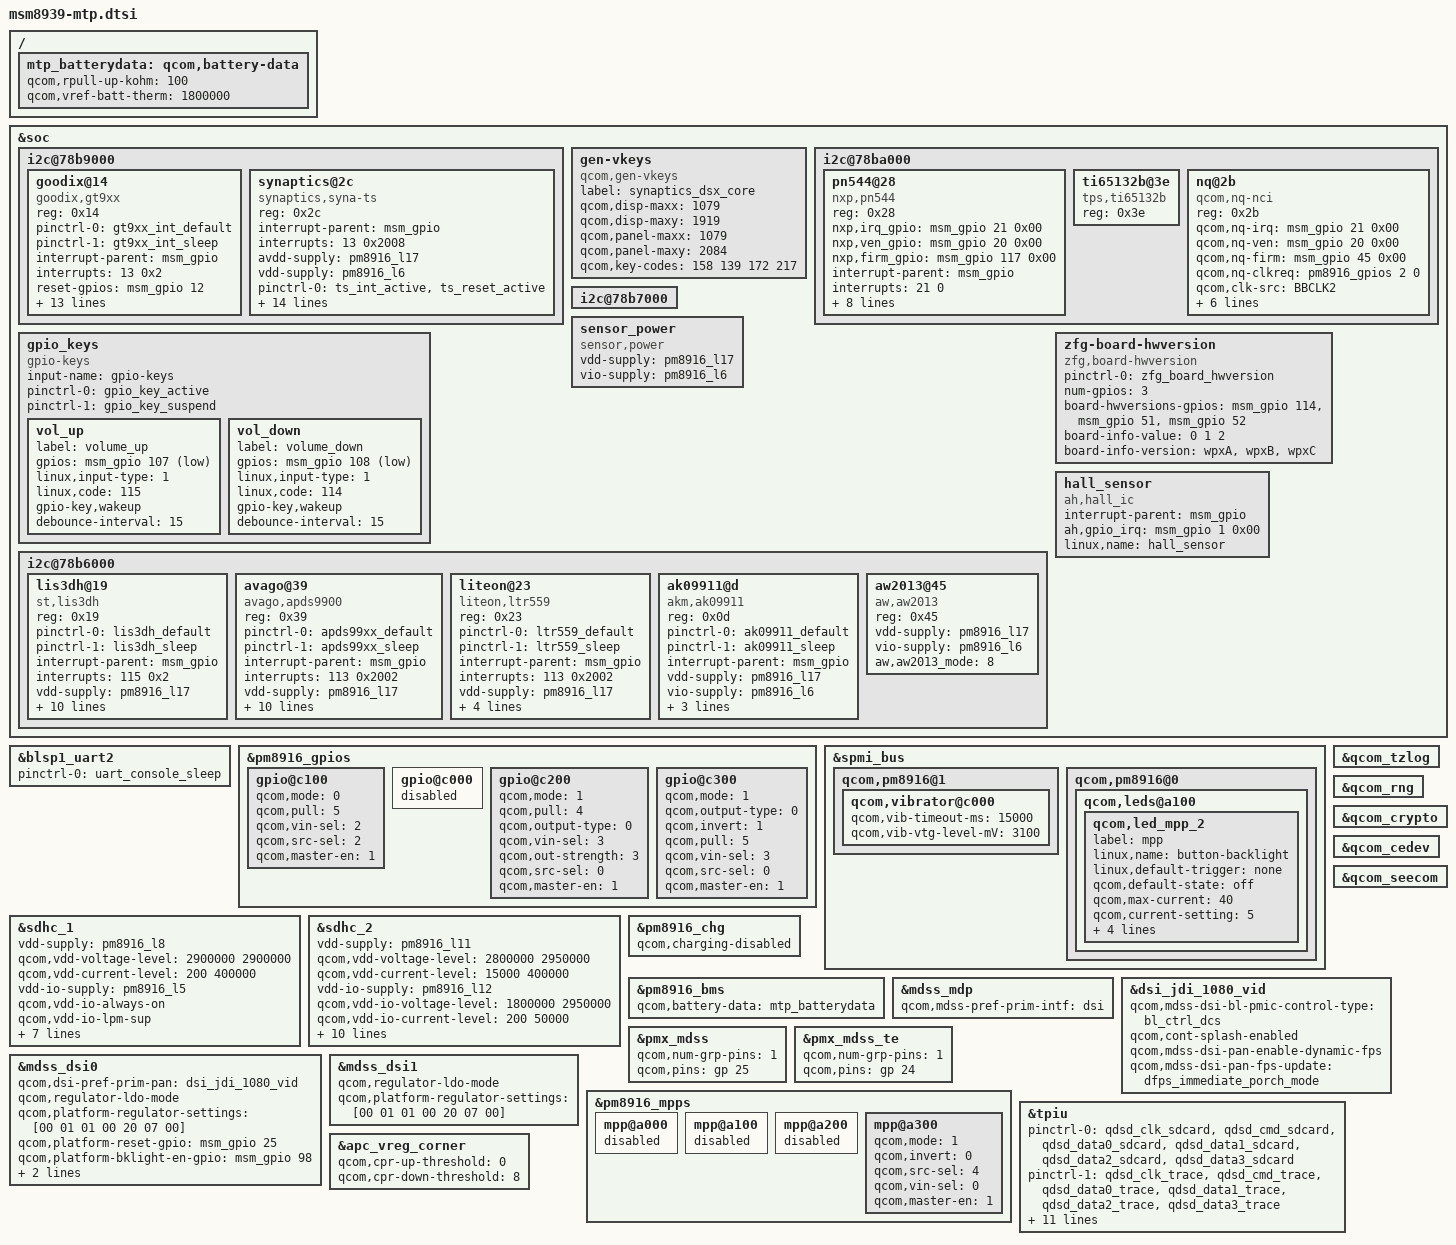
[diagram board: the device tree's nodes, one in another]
/* Copyright (c) 2014-2015, The Linux Foundation. All rights reserved.
 *
 * This program is free software; you can redistribute it and/or modify
 * it under the terms of the GNU General Public License version 2 and
 * only version 2 as published by the Free Software Foundation.
 *
 * This program is distributed in the hope that it will be useful,
 * but WITHOUT ANY WARRANTY; without even the implied warranty of
 * MERCHANTABILITY or FITNESS FOR A PARTICULAR PURPOSE.  See the
 * GNU General Public License for more details.
 */

#include "msm8939-pinctrl.dtsi"
#include "msm8939-camera-sensor-mtp.dtsi"

&soc {
	i2c@78b9000 { /* BLSP1 QUP5 */
                goodix@14 {
            compatible = "goodix,gt9xx";
            reg = <0x14>;
            /* pins used by touchscreen*/
            pinctrl-names = "gt9xx_int_default","gt9xx_int_suspend";
            pinctrl-0 = <&gt9xx_int_default>;
            pinctrl-1 = <&gt9xx_int_sleep>;
            interrupt-parent = <&msm_gpio>;
            interrupts = <13 0x2>;
            reset-gpios = <&msm_gpio 12 0x00>;
            interrupt-gpios = <&msm_gpio 13 0x00>;
            avdd-supply = <&pm8916_l17>;
            vdd-supply = <&pm8916_l17>;
            vcc_i2c-supply = <&pm8916_l6>;
            goodix,panel-coords = <0 0 1080 1920>;
            goodix,display-coords = <0 0 1080 1920>;
            goodix,button-map= <158 172 139>;
            /*regulator-min-microvolt = <2800000>;
            regulator-max-microvolt = <2800000>;*/
            goodix,family-id = <0x0>;
            goodix,no-force-update;
            goodix,slide-wakeup;
            goodix,dbl_clk_wakeup;
            goodix,i2c-pull-up;
            goodix,cfg-data = [];
		};
		synaptics@2c {
			compatible = "synaptics,syna-ts";
			reg = <0x2c>;
			interrupt-parent = <&msm_gpio>;
			interrupts = <13 0x2008>;
			avdd-supply = <&pm8916_l17>;
			vdd-supply = <&pm8916_l6>;
			//synaptics,pwr-reg-name = "avdd";
			//synaptics,bus-reg-name = "vdd";
			/* pins used by touchscreen */
			pinctrl-names = "pmx_ts_active","pmx_ts_suspend";
			pinctrl-0 = <&ts_int_active &ts_reset_active>;
			pinctrl-1 = <&ts_int_suspend &ts_reset_suspend>;
			synaptics,irq-gpio = <&msm_gpio 13 0x2008>;
			synaptics,irq-flags = <0x2008>;
			synaptics,reset-gpio = <&msm_gpio 12 0x0>;
			synaptics,lcd-reset-gpio = <&msm_gpio 25 0>;
			synaptics,vdd-io-gpio = <&msm_gpio 16 0>;
			synaptics,vcc-dc-gpio = <&msm_gpio 112 0>;
			synaptics,disp-debug-en-gpio = <&msm_gpio 119 0>;
			synaptics,i2c-pull-up;
			synaptics,power-down;
			synaptics,disable-gpios;
			synaptics,cap-button-codes = <158 172 139>;
			synaptics,display-coords = <0 0 720 1280>;
			synaptics,panel-coords = <0 0 720 1280>;
		};
	};

	gen-vkeys {
		compatible = "qcom,gen-vkeys";
		label = "synaptics_dsx_core";
		qcom,disp-maxx = <1079>;
		qcom,disp-maxy = <1919>;
		qcom,panel-maxx = <1079>;
		qcom,panel-maxy = <2084>;
		qcom,key-codes = <158 139 172 217>;
	};

	i2c@78ba000 { /* BLSP1 QUP6 */
		//nfc-nci@e {
		//	compatible = "qcom,nfc-nci";
		//	reg = <0x0e>;
		//	qcom,irq-gpio = <&msm_gpio 21 0x00>;
		//	qcom,dis-gpio = <&msm_gpio 20 0x00>;
		//	qcom,clk-src = "BBCLK2";
		//	interrupt-parent = <&msm_gpio>;
		//	interrupts = <21 0>;
		//	interrupt-names = "nfc_irq";
		//	pinctrl-names = "nfc_active","nfc_suspend";
		//	pinctrl-0 = <&nfc_int_active &nfc_disable_active>;
		//	pinctrl-1 = <&nfc_int_suspend &nfc_disable_suspend>;
		//	qcom,clk-gpio = <&pm8916_gpios 2 0>;
		//	clocks = <&clock_rpm clk_bb_clk2_pin>;
		//	clock-names = "ref_clk";
		//};
	pn544@28 {
			compatible = "nxp,pn544";
			reg = <0x28>;
			nxp,irq_gpio = <&msm_gpio 21 0x00>;
			nxp,ven_gpio = <&msm_gpio 20 0x00>;
			nxp,firm_gpio = <&msm_gpio 117 0x00>;
			interrupt-parent = <&msm_gpio>;
			interrupts = <21 0>;
			interrupt-names = "nfc_irq";
			pinctrl-names = "nfc_active","nfc_suspend";
			pinctrl-0 = <&nfc_int_active &nfc_disable_active &nfc_download_active>;
			pinctrl-1 = <&nfc_int_suspend &nfc_disable_suspend &nfc_download_suspend>;
			nxp,clk-src = "BBCLK2";
			nxp,clk-gpio = <&pm8916_gpios 2 0>;
			clocks = <&clock_rpm clk_bb_clk2_pin>;
			clock-names = "ref_clk";
			vdd-supply = <&pm8916_l5>;
		};
		/*yujianhua add start*/
		ti65132b@3e{
			compatible = "tps,ti65132b";
			reg = <0x3e>;
		};
        /*yujianhua add end*/

		nq@2b {
			compatible = "qcom,nq-nci";
			reg = <0x2b>;
			qcom,nq-irq = <&msm_gpio 21 0x00>;
			qcom,nq-ven = <&msm_gpio 20 0x00>;
			qcom,nq-firm = <&msm_gpio 45 0x00>;
			qcom,nq-clkreq = <&pm8916_gpios 2 0>;
			qcom,clk-src = "BBCLK2";
			interrupt-parent = <&msm_gpio>;
			interrupts = <21 0>;
			interrupt-names = "nfc_irq";
			pinctrl-names = "nfc_active","nfc_suspend";
			pinctrl-0 = <&nfc_int_active &nfc_disable_active>;
			pinctrl-1 = <&nfc_int_suspend &nfc_disable_suspend>;
			clocks = <&clock_rpm clk_bb_clk2_pin>;
			clock-names = "ref_clk";
		};
	};
	gpio_keys {
		compatible = "gpio-keys";
		input-name = "gpio-keys";
		pinctrl-names = "tlmm_gpio_key_active","tlmm_gpio_key_suspend";
		pinctrl-0 = <&gpio_key_active>;
		pinctrl-1 = <&gpio_key_suspend>;
                /* 
		camera_focus {
			label = "camera_focus";
			gpios = <&msm_gpio 108 0x1>;
			linux,input-type = <1>;
			linux,code = <0x210>;
			gpio-key,wakeup;
			debounce-interval = <15>;
		};
		*/
                
                /*
		camera_snapshot {
			label = "camera_snapshot";
			gpios = <&msm_gpio 109 0x1>;
			linux,input-type = <1>;
			linux,code = <0x2fe>;
			gpio-key,wakeup;
			debounce-interval = <15>;
		};
		*/
                
		vol_up {
			label = "volume_up";
			gpios = <&msm_gpio 107 0x1>;
			linux,input-type = <1>;
			linux,code = <115>;
			gpio-key,wakeup;
			debounce-interval = <15>;
		};
		vol_down {
			label = "volume_down";
			gpios = <&msm_gpio 108 0x1>;
			linux,input-type = <1>;
			linux,code = <114>;
			gpio-key,wakeup;
			debounce-interval = <15>;
		};
	};
        
	i2c@78b7000 { /* BLSP1 QUP3 */
        

        
	};	
        
        sensor_power {
                compatible = "sensor,power";
                vdd-supply = <&pm8916_l17>;
                vio-supply = <&pm8916_l6>;
	};
        

	i2c@78b6000 { /* BLSP1 QUP2 */
		lis3dh@19 { 
			compatible = "st,lis3dh";
			reg = <0x19>;
			pinctrl-names = "lis3dh_default","lis3dh_sleep";
			pinctrl-0 = <&lis3dh_default>;
			pinctrl-1 = <&lis3dh_sleep>;
			interrupt-parent = <&msm_gpio>;
			interrupts = <115 0x2>;
			vdd-supply = <&pm8916_l17>;
			vddio-supply = <&pm8916_l6>;
			st,gpio-int1 = <&msm_gpio 115 0x2>;
			//st,gpio-int2 = <&msm_gpio 82 0>;
			st,min-interval = <5>;
			st,init-interval = <100>;
			st,axis-map-x = <0>;
			st,axis-map-y = <1>;
			st,axis-map-z = <2>;
			st,g-range = <2>;
			st,negate-x;
			st,negate-y;
		//	st,negate-z;
		};

		avago@39 { /* Ambient light and proximity sensor */
			compatible = "avago,apds9900";
			reg = <0x39>;
			pinctrl-names = "default","sleep";
			pinctrl-0 = <&apds99xx_default>;
			pinctrl-1 = <&apds99xx_sleep>;
			interrupt-parent = <&msm_gpio>;
			interrupts = <113 0x2002>;
			vdd-supply = <&pm8916_l17>;
			vio-supply = <&pm8916_l6>;
			avago,irq-gpio = <&msm_gpio 113 0x2002>;
			avago,ps-threshold = <600>;
			avago,ps-hysteresis-threshold = <500>;
			avago,ps-pulse = <8>;
			avago,ps-pgain = <0>;
			avago,als-B = <186>;
			avago,als-C = <75>;
			avago,als-D = <129>;
			avago,ga-value = <560>;
		};

/*add ALS sensor begin by jiangchong,2014\12\30*/
	    liteon@23 {
		    compatible = "liteon,ltr559";
		    reg = <0x23>;
		    pinctrl-names = "default","sleep";
		    pinctrl-0 = <&ltr559_default>;
		    pinctrl-1 = <&ltr559_sleep>;
			interrupt-parent = <&msm_gpio>;
		    interrupts = <113 0x2002>;
			vdd-supply = <&pm8916_l17>;
			vio-supply = <&pm8916_l6>;
		    liteon,intr = <&msm_gpio 113 0x2002>;
		    liteon,highthr = <180>;
		    liteon,lowthr = <100>;
		};
/*add ALS sensor end by jiangchong,2014\12\30*/

		ak09911@d {
			compatible = "akm,ak09911";
			reg = <0x0d>;	
			pinctrl-names = "ak09911_default", "ak09911_sleep";
			pinctrl-0 = <&ak09911_default>;
			pinctrl-1 = <&ak09911_sleep>;
			interrupt-parent = <&msm_gpio>;
			vdd-supply = <&pm8916_l17>;
			vio-supply = <&pm8916_l6>;
			akm,layout = <1>;
			akm,auto-report;
			akm,gpio_rstn = <&msm_gpio 36 0x00>;
		};

    /*chenyingfang 20141121 for NotifyLight,start*/
		aw2013@45{
			compatible = "aw,aw2013";
			reg = <0x45>;
			vdd-supply = <&pm8916_l17>;
			vio-supply = <&pm8916_l6>;			
			aw,aw2013_mode = <8>;
		};
    /*chenyingfang 20141121 for NotifyLight,end*/
	};
};

&blsp1_uart2 {
	status = "ok";
	pinctrl-names = "default";
	pinctrl-0 = <&uart_console_sleep>;
};

&pm8916_gpios {
	gpio@c100 { /* GPIO 2 */
		/* NFC_CLK_REQ */
		qcom,mode = <0>; /* QPNP_PIN_MODE_DIG_IN */
		qcom,pull = <5>; /* QPNP_PIN_PULL_NO */
		qcom,vin-sel = <2>; /* QPNP_PIN_VIN2 */
		qcom,src-sel = <2>; /* QPNP_PIN_SEL_FUNC_1 */
		qcom,master-en = <1>;
	};
};
&spmi_bus {
	qcom,pm8916@1 {
		qcom,vibrator@c000 {
			status = "okay";
			qcom,vib-timeout-ms = <15000>;
			qcom,vib-vtg-level-mV = <3100>;
		};
	};

	qcom,pm8916@0 {
		qcom,leds@a100 {
			status = "okay";
			qcom,led_mpp_2 {
				label = "mpp";
				linux,name = "button-backlight";
				linux,default-trigger = "none";
				qcom,default-state = "off";
				qcom,max-current = <40>;
				qcom,current-setting = <5>;
				qcom,id = <6>;
				qcom,mode = "manual";
				qcom,source-sel = <1>;
				qcom,mode-ctrl = <0x60>;
			};
		};
	};
};

&sdhc_1 {
	vdd-supply = <&pm8916_l8>;
	qcom,vdd-voltage-level = <2900000 2900000>;
	qcom,vdd-current-level = <200 400000>;

	vdd-io-supply = <&pm8916_l5>;
	qcom,vdd-io-always-on;
	qcom,vdd-io-lpm-sup;
	qcom,vdd-io-voltage-level = <1800000 1800000>;
	qcom,vdd-io-current-level = <200 60000>;

	pinctrl-names = "active", "sleep";
	pinctrl-0 = <&sdc1_clk_on &sdc1_cmd_on &sdc1_data_on>;
	pinctrl-1 = <&sdc1_clk_off &sdc1_cmd_off &sdc1_data_off>;

	qcom,nonremovable;

	status = "ok";
};

&sdhc_2 {
	vdd-supply = <&pm8916_l11>;
	qcom,vdd-voltage-level = <2800000 2950000>;
	qcom,vdd-current-level = <15000 400000>;

	vdd-io-supply = <&pm8916_l12>;
	qcom,vdd-io-voltage-level = <1800000 2950000>;
	qcom,vdd-io-current-level = <200 50000>;

	pinctrl-names = "active", "sleep";
	pinctrl-0 = <&sdc2_clk_on &sdc2_cmd_on &sdc2_data_on &sdc2_cd_on>;
	pinctrl-1 = <&sdc2_clk_off &sdc2_cmd_off &sdc2_data_off &sdc2_cd_off>;

	#address-cells = <0>;
	interrupt-parent = <&sdhc_2>;
	interrupts = <0 1 2>;
	#interrupt-cells = <1>;
	interrupt-map-mask = <0xffffffff>;
	interrupt-map = <0 &intc 0 125 0
			1 &intc 0 221 0
			2 &msm_gpio 38 0>;
	interrupt-names = "hc_irq", "pwr_irq", "status_irq";
	cd-gpios = <&msm_gpio 38 0x1>;

	status = "ok";
};

&pm8916_chg {
	status = "ok";
	qcom,charging-disabled;
};

/ {
	mtp_batterydata: qcom,battery-data {
		qcom,rpull-up-kohm = <100>;
		qcom,vref-batt-therm = <1800000>;

		#include "batterydata-palladium.dtsi"
	};
};

&pm8916_bms {
	status = "ok";
	qcom,battery-data = <&mtp_batterydata>;
};

&qcom_tzlog {
	status = "okay";
};

&qcom_rng {
	status = "okay";
};

&qcom_crypto {
	status = "okay";
};

&qcom_cedev {
	status = "okay";
};

&qcom_seecom {
	status = "okay";
};

#include "dsi-panel-jdi-1080p-video.dtsi"
#include "dsi-panel-r63315-tm-1080p-video.dtsi"
#include "dsi-panel-nt35596-lead-1080p-video.dtsi"
#include "dsi-panel-nt35596-lead-otp-1080p-video.dtsi"
&mdss_mdp {
	qcom,mdss-pref-prim-intf = "dsi";
};

&dsi_jdi_1080_vid {
	qcom,mdss-dsi-bl-pmic-control-type = "bl_ctrl_dcs";
//	qcom,mdss-dsi-bl-pmic-pwm-frequency = <100>;
//	qcom,mdss-dsi-bl-pmic-bank-select = <0>;
//	qcom,mdss-dsi-pwm-gpio = <&pm8916_mpps 4 0>;
	qcom,cont-splash-enabled;
	qcom,mdss-dsi-pan-enable-dynamic-fps;
	qcom,mdss-dsi-pan-fps-update = "dfps_immediate_porch_mode";
};

&pmx_mdss {
	qcom,num-grp-pins = <1>;
	qcom,pins = <&gp 25>;
};

&pmx_mdss_te {
	qcom,num-grp-pins = <1>;
	qcom,pins = <&gp 24>;
};

&mdss_dsi0 {
	pinctrl-names = "mdss_default", "mdss_sleep";
//	pinctrl-0 = <&mdss_dsi_active &mdss_te_active>;
//	pinctrl-1 = <&mdss_dsi_suspend &mdss_te_suspend>;
	qcom,dsi-pref-prim-pan = <&dsi_jdi_1080_vid>;
	qcom,regulator-ldo-mode;
	qcom,platform-regulator-settings = [00 01 01 00 20 07 00];

	//qcom,platform-enable-gpio = <&msm_gpio 97 0>;
	qcom,platform-reset-gpio = <&msm_gpio 25 0>;
	qcom,platform-bklight-en-gpio = <&msm_gpio 98 0>;
	qcom,platform-vsp-gpio = <&msm_gpio 97 0>;
	qcom,platform-vsn-gpio = <&msm_gpio 10 0>;
};

&mdss_dsi1 {
	qcom,regulator-ldo-mode;
	qcom,platform-regulator-settings = [00 01 01 00 20 07 00];
};

&pm8916_mpps {
	mpp@a000 { /* MPP 1 */
		/* VDD_PX */
		status = "disabled";
	};

	mpp@a100 { /* MPP 2 */
		/* HR LED */
		status = "disabled";
	};

	mpp@a200 { /* MPP 3 */
		/* VREF DAC */
		status = "disabled";
	};

	mpp@a300 { /* MPP 4 */
		/* Backlight PWM */
		qcom,mode = <1>;		/* Digital output */
		qcom,invert = <0>;		/* Disable invert */
		qcom,src-sel = <4>;		/* DTEST1 */
		qcom,vin-sel = <0>;		/* VPH_PWR */
		qcom,master-en = <1>;		/* Enable MPP */
	};
};

&pm8916_gpios {
	gpio@c000 { /* GPIO 1 */
		/* Battery UICC Alarm */
		status = "disabled";
	};

	gpio@c100 { /* GPIO 2 */
		/* NFC_CLK_REQ */
		qcom,mode = <0>; /* QPNP_PIN_MODE_DIG_IN */
		qcom,pull = <5>; /* QPNP_PIN_PULL_NO */
		qcom,vin-sel = <2>; /* QPNP_PIN_VIN2 */
		qcom,src-sel = <2>; /* QPNP_PIN_SEL_FUNC_1 */
		qcom,master-en = <1>;
	};

	gpio@c200 { /* GPIO 3 */
		/* External regulator control for WTR */
		//status = "okay";
		qcom,mode = <1>; /* QPNP_PIN_MODE_DIG_IN */
		qcom,pull = <4>; /* QPNP_PIN_PULL_NO */
		qcom,output-type = <0>;
		qcom,vin-sel = <3>; /* QPNP_PIN_VIN2 */
		qcom,out-strength = <3>;
		qcom,src-sel = <0>; /* QPNP_PIN_SEL_FUNC_1 */
		qcom,master-en = <1>;
	};

	gpio@c300 { /* GPIO 4 */
		/* External regulator control for APC */
		
		/* status = "disabled"; */
		qcom,mode = <1>;
		qcom,output-type = <0>;
		qcom,invert = <1>;
		qcom,pull = <5>;
		qcom,vin-sel = <3>;
		/* qcom,out-strength = <2>; */
		qcom,src-sel = <0>;
		qcom,master-en = <1>;
		
	};
};

/* CoreSight */
&tpiu {
	pinctrl-names = "sdcard", "trace", "swduart",
			"swdtrc", "jtag", "spmi";
	/* NIDnT */
	pinctrl-0 = <&qdsd_clk_sdcard &qdsd_cmd_sdcard
		     &qdsd_data0_sdcard &qdsd_data1_sdcard
		     &qdsd_data2_sdcard &qdsd_data3_sdcard>;
	pinctrl-1 = <&qdsd_clk_trace &qdsd_cmd_trace
		     &qdsd_data0_trace &qdsd_data1_trace
		     &qdsd_data2_trace &qdsd_data3_trace>;
	pinctrl-2 = <&qdsd_cmd_swduart &qdsd_data0_swduart
		     &qdsd_data1_swduart &qdsd_data2_swduart
		     &qdsd_data3_swduart>;
	pinctrl-3 = <&qdsd_clk_swdtrc &qdsd_cmd_swdtrc
		     &qdsd_data0_swdtrc &qdsd_data1_swdtrc
		     &qdsd_data2_swdtrc &qdsd_data3_swdtrc>;
	pinctrl-4 = <&qdsd_cmd_jtag &qdsd_data0_jtag
		     &qdsd_data1_jtag &qdsd_data2_jtag
		     &qdsd_data3_jtag>;
	pinctrl-5 = <&qdsd_clk_spmi &qdsd_cmd_spmi
		     &qdsd_data0_spmi &qdsd_data3_spmi>;
};

&apc_vreg_corner {
		qcom,cpr-up-threshold = <0>;
		qcom,cpr-down-threshold = <8>;
};

&soc {
        zfg-board-hwversion {
                compatible = "zfg,board-hwversion";
                status = "okay";
                pinctrl-names = "default";
                pinctrl-0 = <&zfg_board_hwversion>;
                num-gpios = <3>;
                board-hwversions-gpios = <&msm_gpio 114 0>, <&msm_gpio 51 0>, <&msm_gpio 52 0>;
                board-info-value = <0 1 2>;
                board-info-version = "wpxA", "wpxB", "wpxC";
        };
/* add start by jiangchong for Hall sensor driver,20141212*/
	    hall_sensor {
		    compatible = "ah,hall_ic";
		    interrupt-parent = <&msm_gpio>;			
		    ah,gpio_irq = <&msm_gpio 1 0x00>;
		    linux,name = "hall_sensor";	
              };
/* add end by jiangchong for Hall sensor driver,20141212*/		    
};

